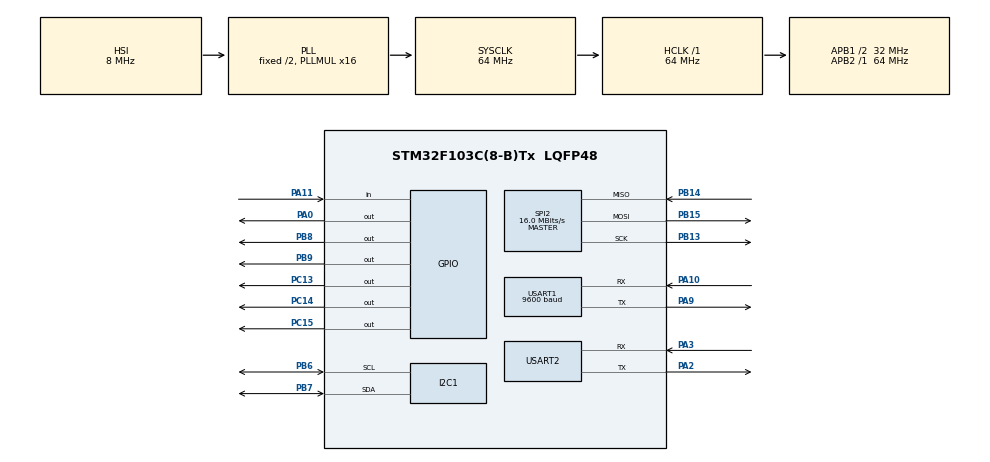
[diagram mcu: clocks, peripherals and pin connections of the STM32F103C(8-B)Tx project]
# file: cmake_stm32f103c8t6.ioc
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Dma.Request0=USART1_RX
Dma.USART1_RX.0.Direction=DMA_PERIPH_TO_MEMORY
Dma.USART1_RX.0.Instance=DMA1_Channel5
Dma.USART1_RX.0.MemDataAlignment=DMA_MDATAALIGN_BYTE
Dma.USART1_RX.0.MemInc=DMA_MINC_ENABLE
Dma.USART1_RX.0.Mode=DMA_NORMAL
Dma.USART1_RX.0.PeriphDataAlignment=DMA_PDATAALIGN_BYTE
Dma.USART1_RX.0.PeriphInc=DMA_PINC_DISABLE
Dma.USART1_RX.0.Priority=DMA_PRIORITY_LOW
Mcu.Family=STM32F1
Mcu.Name=STM32F103C(8-B)Tx
Mcu.Package=LQFP48
NVIC.DMA1_Channel5_IRQn=true\:15\:0\:true\:false\:true\:false\:true\:true
NVIC.PriorityGroup=NVIC_PRIORITYGROUP_4
NVIC.USART1_IRQn=true\:15\:0\:true\:false\:true\:true\:true\:true
NVIC.USART2_IRQn=true\:0\:0\:false\:false\:true\:true\:true\:true
PA0-WKUP.PinState=GPIO_PIN_SET
PA0-WKUP.Signal=GPIO_Output
PA10.Mode=Asynchronous
PA10.Signal=USART1_RX
PA11.GPIO_PuPd=GPIO_PULLDOWN
PA11.Signal=GPIO_Input
PA13.Mode=Serial_Wire
PA13.Signal=SYS_JTMS-SWDIO
PA14.Mode=Serial_Wire
PA14.Signal=SYS_JTCK-SWCLK
PA2.Mode=Asynchronous
PA2.Signal=USART2_TX
PA3.Mode=Asynchronous
PA3.Signal=USART2_RX
PA9.Mode=Asynchronous
PA9.Signal=USART1_TX
PB13.Mode=Full_Duplex_Master
PB13.Signal=SPI2_SCK
PB14.Mode=Full_Duplex_Master
PB14.Signal=SPI2_MISO
PB15.Mode=Full_Duplex_Master
PB15.Signal=SPI2_MOSI
PB6.Mode=I2C
PB6.Signal=I2C1_SCL
PB7.Mode=I2C
PB7.Signal=I2C1_SDA
PB8.Signal=GPIO_Output
PB9.Signal=GPIO_Output
PC13-TAMPER-RTC.PinState=GPIO_PIN_SET
PC13-TAMPER-RTC.Signal=GPIO_Output
PC14-OSC32_IN.PinState=GPIO_PIN_SET
PC14-OSC32_IN.Signal=GPIO_Output
PC15-OSC32_OUT.PinState=GPIO_PIN_SET
PC15-OSC32_OUT.Signal=GPIO_Output
ProjectManager.HeapSize=0x200
ProjectManager.StackSize=0x400
ProjectManager.TargetToolchain=CMake
RCC.AHBFreq_Value=64000000
RCC.APB1CLKDivider=RCC_HCLK_DIV2
RCC.APB1Freq_Value=32000000
RCC.APB1TimFreq_Value=64000000
RCC.APB2Freq_Value=64000000
RCC.APB2TimFreq_Value=64000000
RCC.HCLKFreq_Value=64000000
RCC.PLLMUL=RCC_PLL_MUL16
RCC.SYSCLKFreq_VALUE=64000000
RCC.SYSCLKSource=RCC_SYSCLKSOURCE_PLLCLK
RCC.USBFreq_Value=64000000
SPI2.CalculateBaudRate=16.0 MBits/s
SPI2.Direction=SPI_DIRECTION_2LINES
SPI2.Mode=SPI_MODE_MASTER
SPI2.VirtualType=VM_MASTER
USART1.BaudRate=9600
USART1.Mode=MODE_TX_RX
USART1.VirtualMode=VM_ASYNC
USART2.VirtualMode=VM_ASYNC
board=custom

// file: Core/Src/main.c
/* USER CODE BEGIN Header */
/**
  ******************************************************************************
  * @file           : main.c
  * @brief          : Main program body
  ******************************************************************************
  * @attention
  *
  * Copyright (c) 2024 STMicroelectronics.
  * All rights reserved.
  *
  * This software is licensed under terms that can be found in the LICENSE file
  * in the root directory of this software component.
  * If no LICENSE file comes with this software, it is provided AS-IS.
  *
  ******************************************************************************
  */
/* USER CODE END Header */
#include "main.h"

/* USER CODE BEGIN Includes */
#include"start_main.hpp"
/* USER CODE END Includes */

I2C_HandleTypeDef hi2c1;

SPI_HandleTypeDef hspi2;

UART_HandleTypeDef huart1;
UART_HandleTypeDef huart2;
DMA_HandleTypeDef hdma_usart1_rx;

void SystemClock_Config(void);
static void MX_GPIO_Init(void);
static void MX_DMA_Init(void);
static void MX_USART1_UART_Init(void);
static void MX_USART2_UART_Init(void);
static void MX_SPI2_Init(void);
static void MX_I2C1_Init(void);

int main(void)
{

  /* MCU Configuration--------------------------------------------------------*/

  /* Reset of all peripherals, Initializes the Flash interface and the Systick. */
  HAL_Init();

  /* Configure the system clock */
  SystemClock_Config();

  /* Initialize all configured peripherals */
  MX_GPIO_Init();
  MX_DMA_Init();
  MX_USART1_UART_Init();
  MX_USART2_UART_Init();
  MX_SPI2_Init();
  MX_I2C1_Init();
  /* USER CODE BEGIN 2 */
  start_main();
  /* USER CODE END 2 */

  /* Infinite loop */
  while (1)
  {

  }
}

void SystemClock_Config(void)
{
  RCC_OscInitTypeDef RCC_OscInitStruct = {0};
  RCC_ClkInitTypeDef RCC_ClkInitStruct = {0};

  /** Initializes the RCC Oscillators according to the specified parameters
  * in the RCC_OscInitTypeDef structure.
  */
  RCC_OscInitStruct.OscillatorType = RCC_OSCILLATORTYPE_HSI;
  RCC_OscInitStruct.HSIState = RCC_HSI_ON;
  RCC_OscInitStruct.HSICalibrationValue = RCC_HSICALIBRATION_DEFAULT;
  RCC_OscInitStruct.PLL.PLLState = RCC_PLL_ON;
  RCC_OscInitStruct.PLL.PLLSource = RCC_PLLSOURCE_HSI_DIV2;
  RCC_OscInitStruct.PLL.PLLMUL = RCC_PLL_MUL16;
  if (HAL_RCC_OscConfig(&RCC_OscInitStruct) != HAL_OK)
  {
    Error_Handler();
  }

  /** Initializes the CPU, AHB and APB buses clocks
  */
  RCC_ClkInitStruct.ClockType = RCC_CLOCKTYPE_HCLK|RCC_CLOCKTYPE_SYSCLK
                              |RCC_CLOCKTYPE_PCLK1|RCC_CLOCKTYPE_PCLK2;
  RCC_ClkInitStruct.SYSCLKSource = RCC_SYSCLKSOURCE_PLLCLK;
  RCC_ClkInitStruct.AHBCLKDivider = RCC_SYSCLK_DIV1;
  RCC_ClkInitStruct.APB1CLKDivider = RCC_HCLK_DIV2;
  RCC_ClkInitStruct.APB2CLKDivider = RCC_HCLK_DIV1;

  if (HAL_RCC_ClockConfig(&RCC_ClkInitStruct, FLASH_LATENCY_2) != HAL_OK)
  {
    Error_Handler();
  }
}

static void MX_I2C1_Init(void)
{

  hi2c1.Instance = I2C1;
  hi2c1.Init.ClockSpeed = 100000;
  hi2c1.Init.DutyCycle = I2C_DUTYCYCLE_2;
  hi2c1.Init.OwnAddress1 = 0;
  hi2c1.Init.AddressingMode = I2C_ADDRESSINGMODE_7BIT;
  hi2c1.Init.DualAddressMode = I2C_DUALADDRESS_DISABLE;
  hi2c1.Init.OwnAddress2 = 0;
  hi2c1.Init.GeneralCallMode = I2C_GENERALCALL_DISABLE;
  hi2c1.Init.NoStretchMode = I2C_NOSTRETCH_DISABLE;
  if (HAL_I2C_Init(&hi2c1) != HAL_OK)
  {
    Error_Handler();
  }

}

static void MX_SPI2_Init(void)
{

  /* SPI2 parameter configuration*/
  hspi2.Instance = SPI2;
  hspi2.Init.Mode = SPI_MODE_MASTER;
  hspi2.Init.Direction = SPI_DIRECTION_2LINES;
  hspi2.Init.DataSize = SPI_DATASIZE_8BIT;
  hspi2.Init.CLKPolarity = SPI_POLARITY_LOW;
  hspi2.Init.CLKPhase = SPI_PHASE_1EDGE;
  hspi2.Init.NSS = SPI_NSS_SOFT;
  hspi2.Init.BaudRatePrescaler = SPI_BAUDRATEPRESCALER_2;
  hspi2.Init.FirstBit = SPI_FIRSTBIT_MSB;
  hspi2.Init.TIMode = SPI_TIMODE_DISABLE;
  hspi2.Init.CRCCalculation = SPI_CRCCALCULATION_DISABLE;
  hspi2.Init.CRCPolynomial = 10;
  if (HAL_SPI_Init(&hspi2) != HAL_OK)
  {
    Error_Handler();
  }

}

static void MX_USART1_UART_Init(void)
{

  huart1.Instance = USART1;
  huart1.Init.BaudRate = 9600;
  huart1.Init.WordLength = UART_WORDLENGTH_8B;
  huart1.Init.StopBits = UART_STOPBITS_1;
  huart1.Init.Parity = UART_PARITY_NONE;
  huart1.Init.Mode = UART_MODE_TX_RX;
  huart1.Init.HwFlowCtl = UART_HWCONTROL_NONE;
  huart1.Init.OverSampling = UART_OVERSAMPLING_16;
  if (HAL_UART_Init(&huart1) != HAL_OK)
  {
    Error_Handler();
  }

}

static void MX_USART2_UART_Init(void)
{

  huart2.Instance = USART2;
  huart2.Init.BaudRate = 115200;
  huart2.Init.WordLength = UART_WORDLENGTH_8B;
  huart2.Init.StopBits = UART_STOPBITS_1;
  huart2.Init.Parity = UART_PARITY_NONE;
  huart2.Init.Mode = UART_MODE_TX_RX;
  huart2.Init.HwFlowCtl = UART_HWCONTROL_NONE;
  huart2.Init.OverSampling = UART_OVERSAMPLING_16;
  if (HAL_UART_Init(&huart2) != HAL_OK)
  {
    Error_Handler();
  }

}

static void MX_DMA_Init(void)
{

  /* DMA controller clock enable */
  __HAL_RCC_DMA1_CLK_ENABLE();

  /* DMA interrupt init */
  /* DMA1_Channel5_IRQn interrupt configuration */
  HAL_NVIC_SetPriority(DMA1_Channel5_IRQn, 15, 0);
  HAL_NVIC_EnableIRQ(DMA1_Channel5_IRQn);

}

static void MX_GPIO_Init(void)
{
  GPIO_InitTypeDef GPIO_InitStruct = {0};

  /* GPIO Ports Clock Enable */
  __HAL_RCC_GPIOC_CLK_ENABLE();
  __HAL_RCC_GPIOA_CLK_ENABLE();
  __HAL_RCC_GPIOB_CLK_ENABLE();

  /*Configure GPIO pin Output Level */
  HAL_GPIO_WritePin(GPIOC, GPIO_PIN_13|GPIO_PIN_14|GPIO_PIN_15, GPIO_PIN_SET);

  /*Configure GPIO pin Output Level */
  HAL_GPIO_WritePin(GPIOA, GPIO_PIN_0, GPIO_PIN_SET);

  /*Configure GPIO pin Output Level */
  HAL_GPIO_WritePin(GPIOB, GPIO_PIN_8|GPIO_PIN_9, GPIO_PIN_RESET);

  /*Configure GPIO pins : PC13 PC14 PC15 */
  GPIO_InitStruct.Pin = GPIO_PIN_13|GPIO_PIN_14|GPIO_PIN_15;
  GPIO_InitStruct.Mode = GPIO_MODE_OUTPUT_PP;
  GPIO_InitStruct.Pull = GPIO_NOPULL;
  GPIO_InitStruct.Speed = GPIO_SPEED_FREQ_LOW;
  HAL_GPIO_Init(GPIOC, &GPIO_InitStruct);

  /*Configure GPIO pin : PA0 */
  GPIO_InitStruct.Pin = GPIO_PIN_0;
  GPIO_InitStruct.Mode = GPIO_MODE_OUTPUT_PP;
  GPIO_InitStruct.Pull = GPIO_NOPULL;
  GPIO_InitStruct.Speed = GPIO_SPEED_FREQ_LOW;
  HAL_GPIO_Init(GPIOA, &GPIO_InitStruct);

  /*Configure GPIO pin : PA11 */
  GPIO_InitStruct.Pin = GPIO_PIN_11;
  GPIO_InitStruct.Mode = GPIO_MODE_INPUT;
  GPIO_InitStruct.Pull = GPIO_PULLDOWN;
  HAL_GPIO_Init(GPIOA, &GPIO_InitStruct);

  /*Configure GPIO pins : PB8 PB9 */
  GPIO_InitStruct.Pin = GPIO_PIN_8|GPIO_PIN_9;
  GPIO_InitStruct.Mode = GPIO_MODE_OUTPUT_PP;
  GPIO_InitStruct.Pull = GPIO_NOPULL;
  GPIO_InitStruct.Speed = GPIO_SPEED_FREQ_LOW;
  HAL_GPIO_Init(GPIOB, &GPIO_InitStruct);

}

void Error_Handler(void)
{
  __disable_irq();
  while (1)
  {
  }
}
